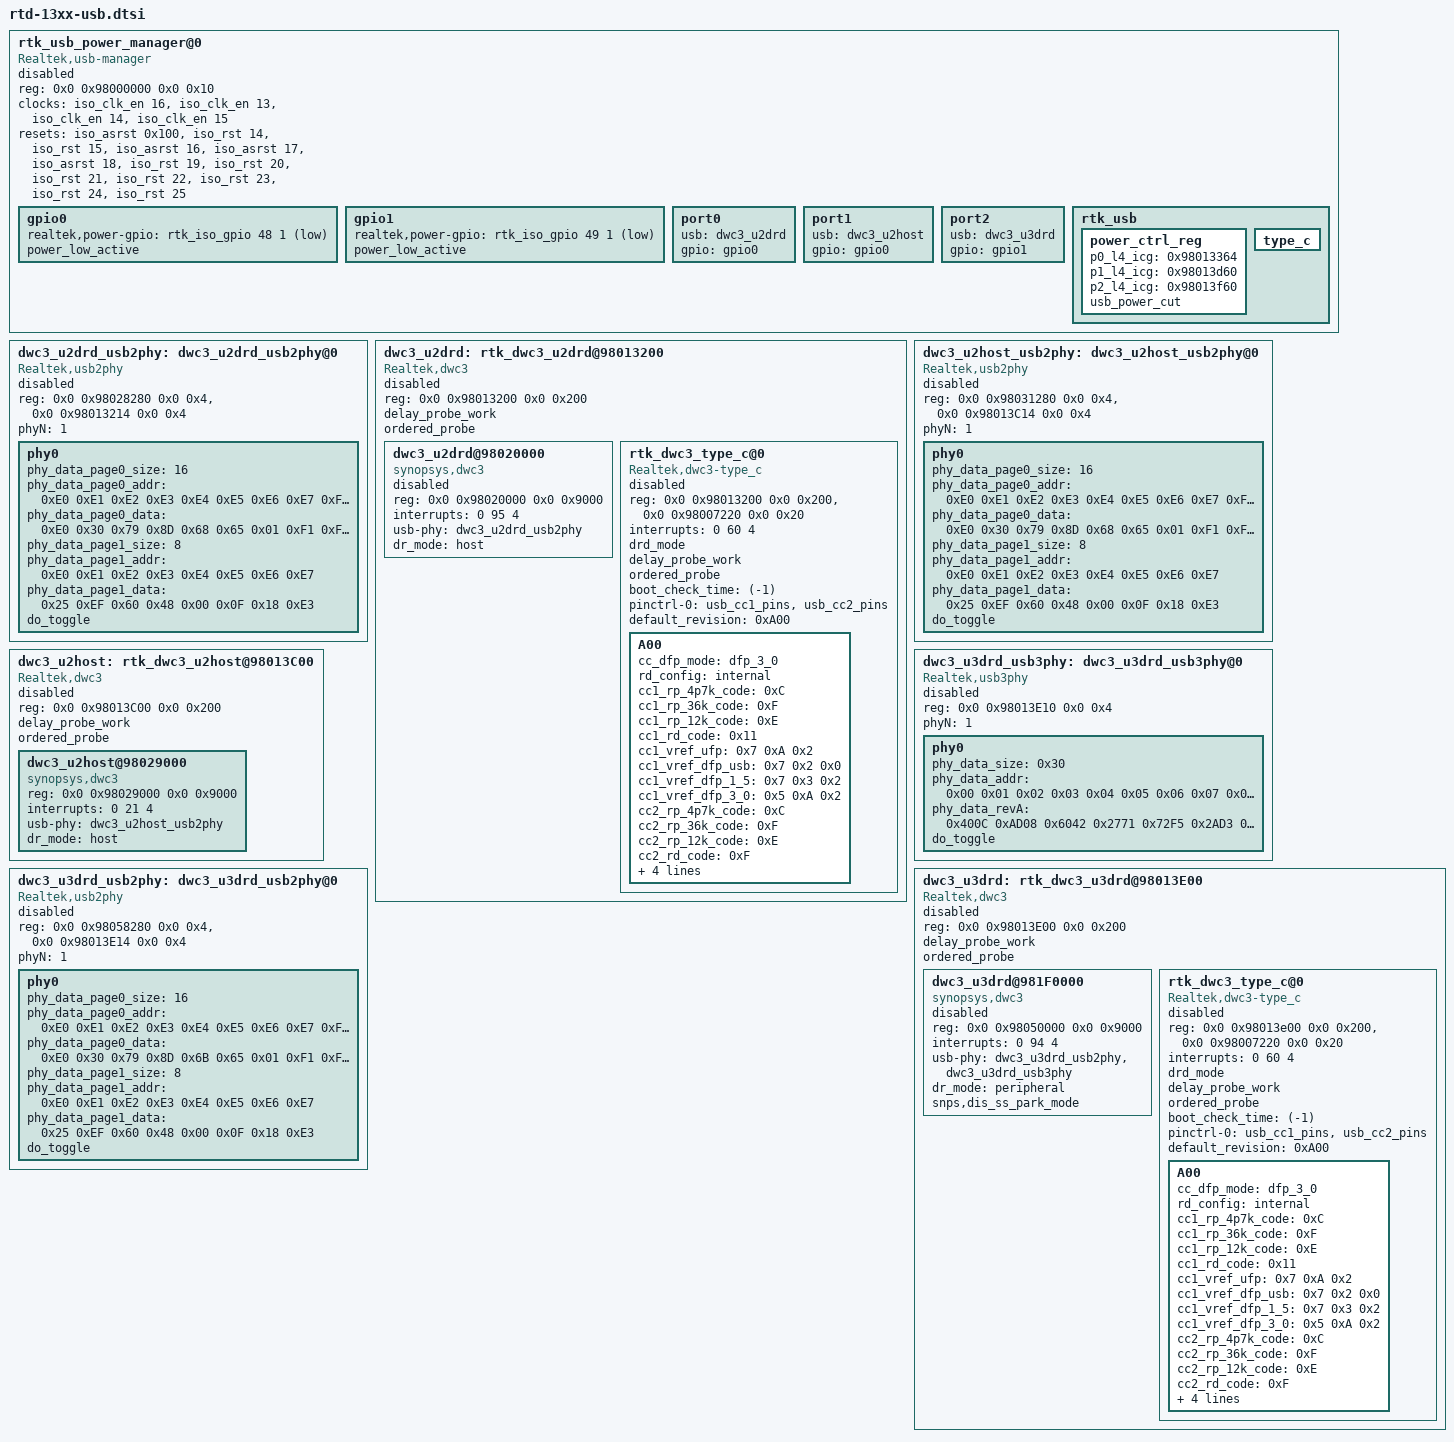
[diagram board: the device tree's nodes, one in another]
/*
 * rtd-13xx-usb.dtsi
 */

	rtk_usb_power_manager@0 {
		compatible = "Realtek,usb-manager";
		reg = <0x0 0x98000000 0x0 0x10>;

		//usb_iso_mode;  /* ISO mode is only port suspend (Default disable) */
		//en_usb_storage_reprobe; /* To enable usb storage re-probe*/
		//rescue_usb; /* For rescue dtb use */

		clocks = <&iso_clk_en 16>, /* clk_en_usb */
			<&iso_clk_en 13>,  /* clk_en_usb_drd (port0 phy to u2drd clock) */
			<&iso_clk_en 14>,  /* clk_en_usb_host0 (port1 phy to u2host clock) */
			<&iso_clk_en 15>;  /* clk_en_usb_host1 (port2 phy to u3drd clock) */
		clock-names = "clk_en_usb", /*clk_en_usb*/
			"clk_en_phy0_to_host", /*clk_en_usb_drd (port0 phy to u2drd clock) */
			"clk_en_phy1_to_host", /*clk_en_usb_u2host (port1 phy to u2host clock */
			"clk_en_phy2_to_host"; /*clk_en_usb_u3host (port2 phy to u3drd clock */

		resets =
			<&iso_asrst 0x100>,
			<&iso_rst 14>, /* rstn_usb_u2drd */
			<&iso_rst 15>, /* rstn_usb_u2host */
			<&iso_asrst 16>, /* rstn_usb_phy0 */
			<&iso_asrst 17>, /* rstn_usb_phy1 */
			<&iso_asrst 18>, /* rstn_usb_phy2 */
			<&iso_rst 19>, /* rstn_usb */
			<&iso_rst 20>, /* rstn_type c */
			<&iso_rst 21>, /* rstn_usb_u3drd */
			<&iso_rst 22>, /* rstn_usb3_phy0 */
			<&iso_rst 23>, /* rstn_usb3_phy0_mdio */
			<&iso_rst 24>, /* rstn_usb3_phy1 */
			<&iso_rst 25>; /* rstn_usb3_phy1_mdio */

		reset-names = "apply",
			"usb_host0", /*rstn_usb_u2drd*/
			"usb_host1", /*rstn_usb_u2host*/
			"u2phy0", /*rstn_usb_phy0*/
			"u2phy1", /*rstn_usb_phy1*/
			"u2phy2", /*rstn_usb_phy2*/
			"usb", /*rstn_usb*/
			"type_c", /*rstn_type_c*/
			"usb_host2", /*rstn_usb_u3drd*/
			"u3phy0", /*rstn_usb3_phy0*/
			"u3mdio0", /*rstn_usb3_phy0_mdio*/
			"u3phy1", /*rstn_usb3_phy1*/
			"u3mdio1"; /*rstn_usb3_phy1_mdio*/

		status = "disabled";

		gpio0: gpio0 {
			realtek,power-gpio = <&rtk_iso_gpio 48 1 3>;
			power_low_active;

		};
		gpio1: gpio1 {
			realtek,power-gpio = <&rtk_iso_gpio 49 1 3>;
			power_low_active;

		};

		port0 {
			usb = <&dwc3_u2drd>;
			//type_c = <&dwc3_type_c>; /* for port 0 type c driver */
			gpio = <&gpio0>;
		};
		port1 {
			usb = <&dwc3_u2host>;
			gpio = <&gpio0>;
		};
		port2 {
			usb = <&dwc3_u3drd>;
			//type_c = <&dwc3_type_c>; /* for port 2 type c driver */
			gpio = <&gpio1>;
		};

		rtk_usb {
			//pcie_usb3phy_sel = <0x9800705c>; /* Only for RTD1319 */

			power_ctrl_reg {
				/* l4_icg */
				p0_l4_icg = <0x98013364>;
				p1_l4_icg = <0x98013d60>;
				p2_l4_icg = <0x98013f60>;

				usb_power_cut; /* Non ISO mode and power cut (Default disable power cut) */
				               /* Note if enable ISO mode, then power_cut will not effective*/
			};
			type_c {
				/* For 1315, 1317, u2drd */
				//realtek,connector_switch-gpio = <&rtk_iso_gpio 25 1 3>;
				/* For 1319, u3drd */
				//realtek,plug_side_switch-gpio = <&rtk_iso_gpio 53 1 3>;
			};
		};
	};

	dwc3_u2drd_usb2phy: dwc3_u2drd_usb2phy@0 {
		compatible = "Realtek,usb2phy";
		reg = <0x0 0x98028280 0x0 0x4>, <0x0 0x98013214 0x0 0x4>;
		#address-cells = <2>;
		#size-cells = <2>;
		ranges;
		status = "disabled";
		phyN = <1>;
		phy0 {
			phy_data_page0_size = <16>;
			phy_data_page0_addr = /bits/ 8
				<0xE0 0xE1 0xE2 0xE3 0xE4 0xE5 0xE6 0xE7 0xF0 0xF1
				0xF2 0xF3 0xF4 0xF5 0xF6 0xF7>;
			phy_data_page0_data = /bits/ 8
				<0xE0 0x30 0x79 0x8D 0x68 0x65 0x01 0xF1 0xFC 0x8C
				0x00 0x11 0x9B 0x00 0x00 0x02>;
			phy_data_page1_size = <8>;
			phy_data_page1_addr = /bits/ 8
				<0xE0 0xE1 0xE2 0xE3 0xE4 0xE5 0xE6 0xE7>;
			phy_data_page1_data = /bits/ 8
				<0x25 0xEF 0x60 0x48 0x00 0x0F 0x18 0xE3>;
			do_toggle;
			//check_efuse;
			//use_default_parameter;
		};
	};

	dwc3_u2drd: rtk_dwc3_u2drd@98013200 {
		compatible = "Realtek,dwc3";
		reg = <0x0 0x98013200 0x0 0x200>;
		#address-cells = <2>;
		#size-cells = <2>;
		ranges;
		delay_probe_work; //To delay probe work
		ordered_probe; // ordered probe in delay work
		status = "disabled";

		dwc3_u2drd@98020000 {
			compatible = "synopsys,dwc3";
			reg = <0x0 0x98020000 0x0 0x9000>;
			interrupts = <0 95 4>;
			usb-phy = <&dwc3_u2drd_usb2phy>;
			dr_mode = "host"; /*otg, host, peripheral*/
			//tx-fifo-resize;
			//snps,dis_u2_susphy_quirk; // Add workaround for Usb3.0 hub suspend

			status = "disabled";
		};

		/* u2drd type_c Only For 1317, 1315 */
		rtk_dwc3_type_c@0 {
			compatible = "Realtek,dwc3-type_c";
			reg = <0x0 0x98013200 0x0 0x200>,  <0x0 0x98007220 0x0 0x20>;
			interrupts = <0 60 4>;
			drd_mode;  /*depend on dwc3 dr_mode = "peripheral"*/
			//debug; /*to enable debug log*/
			delay_probe_work; /*To delay probe work*/
			ordered_probe; /*ordered probe in delay work*/
			boot_check_time = <(-1)>; /*ms (At boot Device switch Host time)*/
			pinctrl-names = "default";
			pinctrl-0 = <&usb_cc1_pins>, <&usb_cc2_pins>;

			status = "disabled";

			default_revision = <0xA00>;
			A00 {
				cc_dfp_mode = "dfp_3_0"; /*dfp_3_0, dfp_1_5, dfp_usb*/
				rd_config = "internal"; /*internal, extrenal*/
				cc1_rp_4p7k_code = <0xC>;
				cc1_rp_36k_code = <0xF>;
				cc1_rp_12k_code = <0xE>;
				cc1_rd_code = <0x11>; /*for internal rd*/
				cc1_vref_ufp = /bits/ 8
					<0x7 0xA 0x2>; /*<1p23v,0p66v,0p2v>*/
				cc1_vref_dfp_usb = /bits/ 8
					<0x7 0x2 0x0>; /*<0_1p6v,0p2v,unused>*/
				cc1_vref_dfp_1_5 = /bits/ 8
					<0x7 0x3 0x2>; /*<1_1p6v,0p4v,0p2v>*/
				cc1_vref_dfp_3_0 = /bits/ 8
					<0x5 0xA 0x2>; /*<2p6v,0p8v,0p2v>*/
				cc2_rp_4p7k_code = <0xC>;
				cc2_rp_36k_code = <0xF>;
				cc2_rp_12k_code = <0xE>;
				cc2_rd_code = <0xF>; /*for internal rd*/
				cc2_vref_ufp = /bits/ 8
					<0x8 0xA 0x2>; /*<1p23v,0p66v,0p2v>*/
				cc2_vref_dfp_usb = /bits/ 8
					<0x7 0x2 0x0>; /*<0_1p6v,0p2v,unused>*/
				cc2_vref_dfp_1_5 = /bits/ 8
					<0x7 0x3 0x2>; /*<1_1p6v,0p4v,0p2v>*/
				cc2_vref_dfp_3_0 = /bits/ 8
					<0x5 0xA 0x2>; /*<2p6v,0p8v,0p2v>*/
			};
		};
	};

	dwc3_u2host_usb2phy: dwc3_u2host_usb2phy@0 {
		compatible = "Realtek,usb2phy";
		reg = <0x0 0x98031280 0x0 0x4>, <0x0 0x98013C14 0x0 0x4>;
		#address-cells = <2>;
		#size-cells = <2>;
		ranges;
		status = "disabled";
		phyN = <1>;
		phy0 {
			phy_data_page0_size = <16>;
			phy_data_page0_addr = /bits/ 8
				<0xE0 0xE1 0xE2 0xE3 0xE4 0xE5 0xE6 0xE7 0xF0 0xF1
				0xF2 0xF3 0xF4 0xF5 0xF6 0xF7>;
			phy_data_page0_data = /bits/ 8
				<0xE0 0x30 0x79 0x8D 0x68 0x65 0x01 0xF1 0xFC 0x8C
				0x00 0x11 0x9B 0x00 0x00 0x02>;
			phy_data_page1_size = <8>;
			phy_data_page1_addr = /bits/ 8
				<0xE0 0xE1 0xE2 0xE3 0xE4 0xE5 0xE6 0xE7>;
			phy_data_page1_data = /bits/ 8
				<0x25 0xEF 0x60 0x48 0x00 0x0F 0x18 0xE3>;
			do_toggle;
			//check_efuse;
			//use_default_parameter;
		};
	};

	dwc3_u2host: rtk_dwc3_u2host@98013C00 {
		compatible = "Realtek,dwc3";
		reg = <0x0 0x98013C00 0x0 0x200>;
		#address-cells = <2>;
		#size-cells = <2>;
		ranges;
		delay_probe_work; //To delay probe work
		ordered_probe; // ordered probe in delay work
		status = "disabled";

		dwc3_u2host@98029000 {
			compatible = "synopsys,dwc3";
			reg = <0x0 0x98029000 0x0 0x9000>;
			interrupts = <0 21 4>;
			usb-phy = <&dwc3_u2host_usb2phy>;
			dr_mode = "host"; /*only host*/
			//tx-fifo-resize;
			//snps,dis_u2_susphy_quirk; // Add workaround for Usb3.0 hub suspend
		};
	};

	dwc3_u3drd_usb3phy: dwc3_u3drd_usb3phy@0 {
		compatible = "Realtek,usb3phy";
		reg = <0x0 0x98013E10 0x0 0x4>;
		#address-cells = <2>;
		#size-cells = <2>;
		ranges;
		status = "disabled";
		phyN = <1>;
		phy0 {
			phy_data_size = <0x30>;
			phy_data_addr = /bits/ 8
				<0x00 0x01 0x02 0x03 0x04 0x05 0x06
				0x07 0x08 0x09 0x0A 0x0B 0x0C 0x0D
				0x0E 0x0F 0x10 0x11 0x12 0x13 0x14
				0x15 0x16 0x17 0x18 0x19 0x1A 0x1B
				0x1C 0x1D 0x1E 0x1F 0x20 0x21 0x22
				0x23 0x24 0x25 0x26 0x27 0x28 0x29
				0x2A 0x2B 0x2C 0x2D 0x2E 0x2F>;
			phy_data_revA = /bits/ 16
				<0x400C 0xAD08 0x6042 0x2771 0x72F5 0x2AD3 0x0003
				 0x2E00 0x3591 0x565C 0xB608 0xA905 0xC000 0xEF1E
				 0x2000 0x8D50 0x000C 0x4C10 0xFC00 0x0C81 0xDE01
				 0x0000 0x0000 0x0000 0x0000 0x6000 0x0085 0x2014
				 0xC900 0xA03F 0xC2E0 0x7E00 0x70AA 0x88AA 0x0053
				 0xAB66 0x4770 0x126C 0x840A 0x01D6 0xF802 0xff00
				 0x3040 0x8028 0xFFFF 0xFFFF 0x0000 0x8600>;
			do_toggle;
			//use_default_parameter;
		};
	};

	dwc3_u3drd_usb2phy: dwc3_u3drd_usb2phy@0 {
		compatible = "Realtek,usb2phy";
		reg = <0x0 0x98058280 0x0 0x4>, <0x0 0x98013E14 0x0 0x4>;
		#address-cells = <2>;
		#size-cells = <2>;
		ranges;
		status = "disabled";
		phyN = <1>;
		phy0 {
			phy_data_page0_size = <16>;
			phy_data_page0_addr = /bits/ 8
				<0xE0 0xE1 0xE2 0xE3 0xE4 0xE5 0xE6 0xE7 0xF0 0xF1
				0xF2 0xF3 0xF4 0xF5 0xF6 0xF7>;
			phy_data_page0_data = /bits/ 8
				<0xE0 0x30 0x79 0x8D 0x6B 0x65 0x01 0xF1 0xFC 0x8C
				0x00 0x11 0x9B 0x00 0x00 0x02>;
			phy_data_page1_size = <8>;
			phy_data_page1_addr = /bits/ 8
				<0xE0 0xE1 0xE2 0xE3 0xE4 0xE5 0xE6 0xE7>;
			phy_data_page1_data = /bits/ 8
				<0x25 0xEF 0x60 0x48 0x00 0x0F 0x18 0xE3>;
			do_toggle;
			//check_efuse;
			//use_default_parameter;
		};
	};

	dwc3_u3drd: rtk_dwc3_u3drd@98013E00 {
		compatible = "Realtek,dwc3";
		reg = <0x0 0x98013E00 0x0 0x200>;
		#address-cells = <2>;
		#size-cells = <2>;
		ranges;
		delay_probe_work; //To delay probe work
		ordered_probe; // ordered probe in delay work

		status = "disabled";

		dwc3_u3drd@981F0000 {
			compatible = "synopsys,dwc3";
			reg = <0x0 0x98050000 0x0 0x9000>;
			interrupts = <0 94 4>;
			usb-phy = <&dwc3_u3drd_usb2phy &dwc3_u3drd_usb3phy>;
			dr_mode = "peripheral"; /*only host*/
			//tx-fifo-resize;
			//snps,dis_u2_susphy_quirk; // Add workaround for Usb3.0 hub suspend
			snps,dis_ss_park_mode; // disable usb3.0 park mode

			status = "disabled";
		};

		/* u3drd type_c Only For 1319 */
		rtk_dwc3_type_c@0 {
			compatible = "Realtek,dwc3-type_c";
			reg = <0x0 0x98013e00 0x0 0x200>,  <0x0 0x98007220 0x0 0x20>;
			interrupts = <0 60 4>;
			drd_mode;  /*depend on dwc3 dr_mode = "peripheral"*/
			//debug; /*to enable debug log*/
			delay_probe_work; /*To delay probe work*/
			ordered_probe; /*ordered probe in delay work*/
			boot_check_time = <(-1)>; /*ms (At boot Device switch Host time)*/
			pinctrl-names = "default";
			pinctrl-0 = <&usb_cc1_pins>, <&usb_cc2_pins>;

			status = "disabled";

			default_revision = <0xA00>;
			A00 {
				cc_dfp_mode = "dfp_3_0"; /*dfp_3_0, dfp_1_5, dfp_usb*/
				rd_config = "internal"; /*internal, extrenal*/
				cc1_rp_4p7k_code = <0xC>;
				cc1_rp_36k_code = <0xF>;
				cc1_rp_12k_code = <0xE>;
				cc1_rd_code = <0x11>; /*for internal rd*/
				cc1_vref_ufp = /bits/ 8
					<0x7 0xA 0x2>; /*<1p23v,0p66v,0p2v>*/
				cc1_vref_dfp_usb = /bits/ 8
					<0x7 0x2 0x0>; /*<0_1p6v,0p2v,unused>*/
				cc1_vref_dfp_1_5 = /bits/ 8
					<0x7 0x3 0x2>; /*<1_1p6v,0p4v,0p2v>*/
				cc1_vref_dfp_3_0 = /bits/ 8
					<0x5 0xA 0x2>; /*<2p6v,0p8v,0p2v>*/
				cc2_rp_4p7k_code = <0xC>;
				cc2_rp_36k_code = <0xF>;
				cc2_rp_12k_code = <0xE>;
				cc2_rd_code = <0xF>; /*for internal rd*/
				cc2_vref_ufp = /bits/ 8
					<0x8 0xA 0x2>; /*<1p23v,0p66v,0p2v>*/
				cc2_vref_dfp_usb = /bits/ 8
					<0x7 0x2 0x0>; /*<0_1p6v,0p2v,unused>*/
				cc2_vref_dfp_1_5 = /bits/ 8
					<0x7 0x3 0x2>; /*<1_1p6v,0p4v,0p2v>*/
				cc2_vref_dfp_3_0 = /bits/ 8
					<0x5 0xA 0x2>; /*<2p6v,0p8v,0p2v>*/
			};
		};
	};

